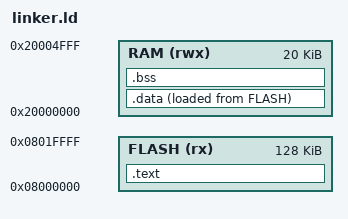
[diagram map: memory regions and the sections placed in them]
MEMORY
{
    FLASH (rx)  : ORIGIN = 0x08000000, LENGTH = 128K
    RAM   (rwx) : ORIGIN = 0x20000000, LENGTH = 20K
}

SECTIONS
{
    .text :
    {
        *(.vectors)
        *(.text*)
        *(.rodata*)
    } > FLASH

    .data :
    {
        _sdata = .;
        *(.data*)
        _edata = .;
    } > RAM AT > FLASH
    _sidata = LOADADDR(.data);

    .bss :
    {
        _sbss = .;
        *(.bss*)
        _ebss = .;
    } > RAM
}
